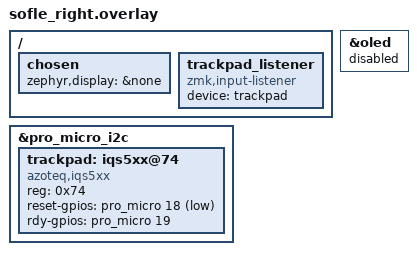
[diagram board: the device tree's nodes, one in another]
// Azoteq TPS43 trackpad configuration for right side
// Right side has NO OLED, only trackpad on I2C bus
// SDA: P0.17 (D2), SCL: P0.20 (D3)

/ {
    // Remove OLED from chosen on right side (it's only on left)
    chosen {
        zephyr,display = &none;
    };

    // Input listener for trackpad (pattern from Research.md)
    trackpad_listener: trackpad_listener {
        compatible = "zmk,input-listener";
        device = <&trackpad>;
    };
};

// Disable OLED on right side since it doesn't exist
&oled {
    status = "disabled";
};

&pro_micro_i2c {
    status = "okay";  // Explicitly enable I2C bus

    trackpad: iqs5xx@74 {
        compatible = "azoteq,iqs5xx";
        reg = <0x74>; // TPS43 I2C address (standard is 0x74)
        status = "okay";

        // REQUIRED: Driver needs both RDY and RESET GPIOs
        // Using back pad pins that don't conflict with encoders or other peripherals
        // Pro Micro pin 18 = P1.04, pin 19 = P1.02
        reset-gpios = <&pro_micro 18 GPIO_ACTIVE_LOW>;
        rdy-gpios = <&pro_micro 19 GPIO_ACTIVE_HIGH>;

        // Start with just basic movement - no gestures
        // Uncomment features one at a time after basic movement works:
        // one-finger-tap;      // Enable tap-to-click (left click)
        // two-finger-tap;      // Enable two-finger tap (right click)
        // press-and-hold;      // Enable press and hold for dragging
        // scroll;              // Enable scrolling
    };
};
